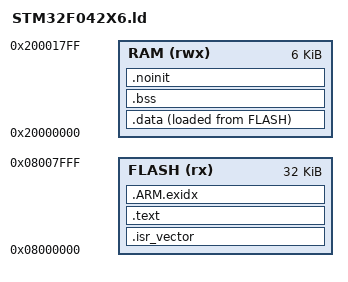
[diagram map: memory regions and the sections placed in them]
/* STM32F042F6P6: 32 KB flash, 6 KB SRAM */
MEMORY
{
  FLASH (rx)  : ORIGIN = 0x08000000, LENGTH = 32K
  RAM   (rwx) : ORIGIN = 0x20000000, LENGTH = 6K
}

_estack = ORIGIN(RAM) + LENGTH(RAM);

SECTIONS
{
  .isr_vector :
  {
    KEEP(*(.isr_vector))
  } > FLASH

  .text :
  {
    *(.text*)
    *(.rodata*)
    KEEP(*(.init))
    KEEP(*(.fini))
    . = ALIGN(4);
  } > FLASH

  .ARM.exidx : { *(.ARM.exidx*) } > FLASH

  _sidata = LOADADDR(.data);
  .data :
  {
    _sdata = .;
    *(.data*)
    . = ALIGN(4);
    _edata = .;
  } > RAM AT > FLASH

  .bss (NOLOAD) :
  {
    _sbss = .;
    *(.bss*)
    *(COMMON)
    . = ALIGN(4);
    _ebss = .;
  } > RAM

  /* Survives a software reset: used to request the system bootloader. */
  .noinit (NOLOAD) :
  {
    *(.noinit*)
    . = ALIGN(4);
  } > RAM

  /DISCARD/ : { *(.ARM.attributes) *(.comment) }
}
